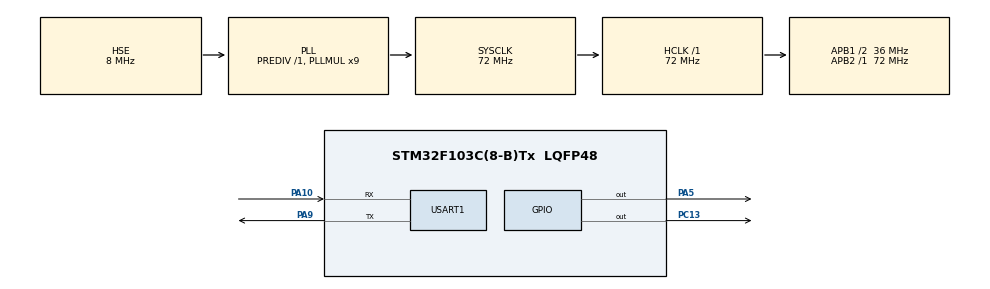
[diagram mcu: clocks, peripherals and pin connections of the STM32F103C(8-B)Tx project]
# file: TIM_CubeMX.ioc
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Mcu.Family=STM32F1
Mcu.Name=STM32F103C(8-B)Tx
Mcu.Package=LQFP48
NVIC.PriorityGroup=NVIC_PRIORITYGROUP_4
NVIC.TIM2_IRQn=true\:0\:0\:false\:true\:true\:1\:true\:true\:true
NVIC.USART1_IRQn=true\:0\:0\:false\:false\:true\:true\:true\:true
PA10.Mode=Asynchronous
PA10.Signal=USART1_RX
PA13.Mode=Serial_Wire
PA13.Signal=SYS_JTMS-SWDIO
PA14.Mode=Serial_Wire
PA14.Signal=SYS_JTCK-SWCLK
PA5.Signal=GPIO_Output
PA9.Mode=Asynchronous
PA9.Signal=USART1_TX
PC13-TAMPER-RTC.Signal=GPIO_Output
PD0-OSC_IN.Mode=HSE-External-Oscillator
PD0-OSC_IN.Signal=RCC_OSC_IN
PD1-OSC_OUT.Mode=HSE-External-Oscillator
PD1-OSC_OUT.Signal=RCC_OSC_OUT
ProjectManager.HeapSize=0x200
ProjectManager.StackSize=0x400
ProjectManager.TargetToolchain=MDK-ARM V5.32
RCC.AHBFreq_Value=72000000
RCC.APB1CLKDivider=RCC_HCLK_DIV2
RCC.APB1Freq_Value=36000000
RCC.APB1TimFreq_Value=72000000
RCC.APB2Freq_Value=72000000
RCC.APB2TimFreq_Value=72000000
RCC.HCLKFreq_Value=72000000
RCC.PLLMUL=RCC_PLL_MUL9
RCC.PLLSourceVirtual=RCC_PLLSOURCE_HSE
RCC.SYSCLKFreq_VALUE=72000000
RCC.SYSCLKSource=RCC_SYSCLKSOURCE_PLLCLK
RCC.USBFreq_Value=72000000
TIM2.AutoReloadPreload=TIM_AUTORELOAD_PRELOAD_ENABLE
TIM2.Period=1000
TIM2.Prescaler=71
USART1.VirtualMode=VM_ASYNC
VP_TIM2_VS_ClockSourceINT.Mode=Internal
board=custom

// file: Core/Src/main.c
/* USER CODE BEGIN Header */
/**
  ******************************************************************************
  * @file           : main.c
  * @brief          : Main program body
  ******************************************************************************
  * @attention
  *
  * Copyright (c) 2022 STMicroelectronics.
  * All rights reserved.
  *
  * This software is licensed under terms that can be found in the LICENSE file
  * in the root directory of this software component.
  * If no LICENSE file comes with this software, it is provided AS-IS.
  *
  ******************************************************************************
  */
/* USER CODE END Header */
#include "main.h"
#include "tim.h"
#include "usart.h"
#include "gpio.h"

void SystemClock_Config(void);
static void MX_NVIC_Init(void);

/* USER CODE BEGIN 0 */

#define COUNTOF(a) (sizeof(a)/sizeof(*(a)))
uint8_t str[] = "Hello ppqppl!\r\n";

void HAL_TIM_PeriodElapsedCallback(TIM_HandleTypeDef *htim){

	static int time = 0;

	if(htim->Instance == TIM2){
		time++;
		if(time%1000 == 0){
				HAL_GPIO_TogglePin(GPIOC,GPIO_PIN_13);
		}
		if(time%2500 == 0){
				HAL_UART_Transmit(&huart1,(uint8_t *)str,sizeof(str),0xFFFF);
				if(time%5000 == 0 && time != 0){
					time = 0;
				}
		}
	}
}

/* USER CODE END 0 */

int main(void)
{

  /* MCU Configuration--------------------------------------------------------*/

  /* Reset of all peripherals, Initializes the Flash interface and the Systick. */
  HAL_Init();

  /* Configure the system clock */
  SystemClock_Config();

  /* Initialize all configured peripherals */
  MX_GPIO_Init();
  MX_TIM2_Init();
  MX_USART1_UART_Init();

  /* Initialize interrupts */
  MX_NVIC_Init();

  /* Infinite loop */
  /* USER CODE BEGIN WHILE */

	HAL_TIM_Base_Start_IT(&htim2);

  while (1)
  {
    /* USER CODE END WHILE */

  }
}

void SystemClock_Config(void)
{
  RCC_OscInitTypeDef RCC_OscInitStruct = {0};
  RCC_ClkInitTypeDef RCC_ClkInitStruct = {0};

  /** Initializes the RCC Oscillators according to the specified parameters
  * in the RCC_OscInitTypeDef structure.
  */
  RCC_OscInitStruct.OscillatorType = RCC_OSCILLATORTYPE_HSE;
  RCC_OscInitStruct.HSEState = RCC_HSE_ON;
  RCC_OscInitStruct.HSEPredivValue = RCC_HSE_PREDIV_DIV1;
  RCC_OscInitStruct.HSIState = RCC_HSI_ON;
  RCC_OscInitStruct.PLL.PLLState = RCC_PLL_ON;
  RCC_OscInitStruct.PLL.PLLSource = RCC_PLLSOURCE_HSE;
  RCC_OscInitStruct.PLL.PLLMUL = RCC_PLL_MUL9;
  if (HAL_RCC_OscConfig(&RCC_OscInitStruct) != HAL_OK)
  {
    Error_Handler();
  }

  /** Initializes the CPU, AHB and APB buses clocks
  */
  RCC_ClkInitStruct.ClockType = RCC_CLOCKTYPE_HCLK|RCC_CLOCKTYPE_SYSCLK
                              |RCC_CLOCKTYPE_PCLK1|RCC_CLOCKTYPE_PCLK2;
  RCC_ClkInitStruct.SYSCLKSource = RCC_SYSCLKSOURCE_PLLCLK;
  RCC_ClkInitStruct.AHBCLKDivider = RCC_SYSCLK_DIV1;
  RCC_ClkInitStruct.APB1CLKDivider = RCC_HCLK_DIV2;
  RCC_ClkInitStruct.APB2CLKDivider = RCC_HCLK_DIV1;

  if (HAL_RCC_ClockConfig(&RCC_ClkInitStruct, FLASH_LATENCY_2) != HAL_OK)
  {
    Error_Handler();
  }
}

/**
  * @brief NVIC Configuration.
  * @retval None
  */
static void MX_NVIC_Init(void)
{
  /* TIM2_IRQn interrupt configuration */
  HAL_NVIC_SetPriority(TIM2_IRQn, 0, 0);
  HAL_NVIC_EnableIRQ(TIM2_IRQn);
}

void Error_Handler(void)
{
  __disable_irq();
  while (1)
  {
  }
}
